AUTOSAR XML (schema 3.1.2)
package /Components/SWC_VSLim
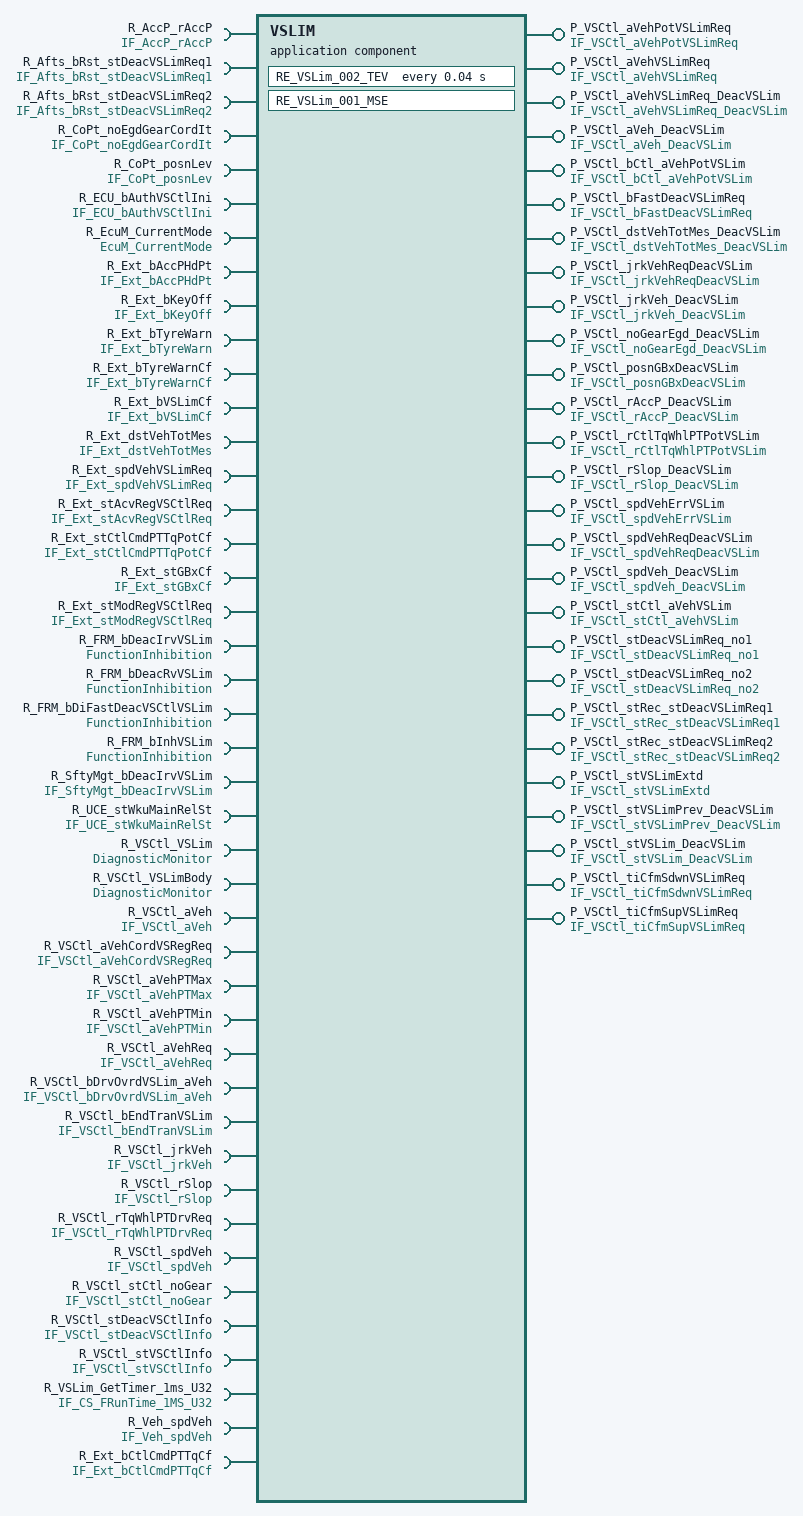
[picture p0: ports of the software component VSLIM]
  application software component type VSLIM  # VSLim
    27 x provide port:
      P_VSCtl_aVehPotVSLimReq: unqueued-sender-com-spec{data-element=VSCtl_aVehPotVSLimReq, can-invalidate=false, init-value=ConstantValue}, provided-interface=IF_VSCtl_aVehPotVSLimReq
      P_VSCtl_aVehVSLimReq: unqueued-sender-com-spec{data-element=VSCtl_aVehVSLimReq, can-invalidate=false, init-value=ConstantValue1}, provided-interface=IF_VSCtl_aVehVSLimReq
      P_VSCtl_aVehVSLimReq_DeacVSLim: unqueued-sender-com-spec{data-element=VSCtl_aVehVSLimReq_DeacVSLim, can-invalidate=false, init-value=C_SInt16_10240}, provided-interface=IF_VSCtl_aVehVSLimReq_DeacVSLim
      P_VSCtl_aVeh_DeacVSLim: unqueued-sender-com-spec{data-element=VSCtl_aVeh_DeacVSLim, can-invalidate=false, init-value=C_SInt16_0}, provided-interface=IF_VSCtl_aVeh_DeacVSLim
      P_VSCtl_bCtl_aVehPotVSLim: unqueued-sender-com-spec{data-element=VSCtl_bCtl_aVehPotVSLim, can-invalidate=false, init-value=ConstantValue3}, provided-interface=IF_VSCtl_bCtl_aVehPotVSLim
      P_VSCtl_bFastDeacVSLimReq: unqueued-sender-com-spec{data-element=VSCtl_bFastDeacVSLimReq, can-invalidate=false, init-value=C_Boolean_False}, provided-interface=IF_VSCtl_bFastDeacVSLimReq
      P_VSCtl_dstVehTotMes_DeacVSLim: unqueued-sender-com-spec{data-element=VSCtl_dstVehTotMes_DeacVSLim, can-invalidate=false, init-value=C_UInt32_0}, provided-interface=IF_VSCtl_dstVehTotMes_DeacVSLim
      P_VSCtl_jrkVehReqDeacVSLim: unqueued-sender-com-spec{data-element=VSCtl_jrkVehReqDeacVSLim, can-invalidate=false, init-value=C_SInt16_05}, provided-interface=IF_VSCtl_jrkVehReqDeacVSLim
      P_VSCtl_jrkVeh_DeacVSLim: unqueued-sender-com-spec{data-element=VSCtl_jrkVeh_DeacVSLim, can-invalidate=false, init-value=C_SInt16_07}, provided-interface=IF_VSCtl_jrkVeh_DeacVSLim
      P_VSCtl_noGearEgd_DeacVSLim: unqueued-sender-com-spec{data-element=VSCtl_noGearEgd_DeacVSLim, can-invalidate=false, init-value=C_SInt8_0}, provided-interface=IF_VSCtl_noGearEgd_DeacVSLim
      P_VSCtl_posnGBxDeacVSLim: unqueued-sender-com-spec{data-element=VSCtl_posnGBxDeacVSLim, can-invalidate=false, init-value=C_UInt8_0}, provided-interface=IF_VSCtl_posnGBxDeacVSLim
      P_VSCtl_rAccP_DeacVSLim: unqueued-sender-com-spec{data-element=VSCtl_rAccP_DeacVSLim, can-invalidate=false, init-value=C_UInt16_12800}, provided-interface=IF_VSCtl_rAccP_DeacVSLim
      P_VSCtl_rCtlTqWhlPTPotVSLim: unqueued-sender-com-spec{data-element=VSCtl_rCtlTqWhlPTPotVSLim, can-invalidate=false, init-value=ConstantValue9}, provided-interface=IF_VSCtl_rCtlTqWhlPTPotVSLim
      P_VSCtl_rSlop_DeacVSLim: unqueued-sender-com-spec{data-element=VSCtl_rSlop_DeacVSLim, can-invalidate=false, init-value=C_SInt16_011}, provided-interface=IF_VSCtl_rSlop_DeacVSLim
      P_VSCtl_spdVehErrVSLim: unqueued-sender-com-spec{data-element=VSCtl_spdVehErrVSLim, can-invalidate=false, init-value=C_SInt16_013}, provided-interface=IF_VSCtl_spdVehErrVSLim
      P_VSCtl_spdVehReqDeacVSLim: unqueued-sender-com-spec{data-element=VSCtl_spdVehReqDeacVSLim, can-invalidate=false, init-value=C_UInt8_015}, provided-interface=IF_VSCtl_spdVehReqDeacVSLim
      P_VSCtl_spdVeh_DeacVSLim: unqueued-sender-com-spec{data-element=VSCtl_spdVeh_DeacVSLim, can-invalidate=false, init-value=C_UInt16_0}, provided-interface=IF_VSCtl_spdVeh_DeacVSLim
      P_VSCtl_stCtl_aVehVSLim: unqueued-sender-com-spec{data-element=VSCtl_stCtl_aVehVSLim, can-invalidate=false, init-value=ConstantValue17}, provided-interface=IF_VSCtl_stCtl_aVehVSLim
      P_VSCtl_stDeacVSLimReq_no1: unqueued-sender-com-spec{data-element=VSCtl_stDeacVSLimReq_no1, can-invalidate=false, init-value=C_UInt32_16777215}, provided-interface=IF_VSCtl_stDeacVSLimReq_no1
      P_VSCtl_stDeacVSLimReq_no2: unqueued-sender-com-spec{data-element=VSCtl_stDeacVSLimReq_no2, can-invalidate=false, init-value=C_UInt32_1677721519}, provided-interface=IF_VSCtl_stDeacVSLimReq_no2
      P_VSCtl_stRec_stDeacVSLimReq1: unqueued-sender-com-spec{data-element=VSCtl_stRec_stDeacVSLimReq1, can-invalidate=false, init-value=C_UInt8_021}, provided-interface=IF_VSCtl_stRec_stDeacVSLimReq1
      P_VSCtl_stRec_stDeacVSLimReq2: unqueued-sender-com-spec{data-element=VSCtl_stRec_stDeacVSLimReq2, can-invalidate=false, init-value=C_UInt8_023}, provided-interface=IF_VSCtl_stRec_stDeacVSLimReq2
      P_VSCtl_stVSLimExtd: unqueued-sender-com-spec{data-element=VSCtl_stVSLimExtd, can-invalidate=false, init-value=C_UInt8_025}, provided-interface=IF_VSCtl_stVSLimExtd
      P_VSCtl_stVSLimPrev_DeacVSLim: unqueued-sender-com-spec{data-element=VSCtl_stVSLimPrev_DeacVSLim, can-invalidate=false, init-value=C_UInt8_027}, provided-interface=IF_VSCtl_stVSLimPrev_DeacVSLim
      P_VSCtl_stVSLim_DeacVSLim: unqueued-sender-com-spec{data-element=VSCtl_stVSLim_DeacVSLim, can-invalidate=false, init-value=C_UInt8_029}, provided-interface=IF_VSCtl_stVSLim_DeacVSLim
      P_VSCtl_tiCfmSdwnVSLimReq: unqueued-sender-com-spec{data-element=VSCtl_tiCfmSdwnVSLimReq, can-invalidate=false, init-value=ConstantValue31}, provided-interface=IF_VSCtl_tiCfmSdwnVSLimReq
      P_VSCtl_tiCfmSupVSLimReq: unqueued-sender-com-spec{data-element=VSCtl_tiCfmSupVSLimReq, can-invalidate=false, init-value=ConstantValue33}, provided-interface=IF_VSCtl_tiCfmSupVSLimReq
    43 x require port:
      R_AccP_rAccP: unqueued-receiver-com-spec{data-element=AccP_rAccP, init-value=ConstantValue35, resync-time=0}, required-interface=IF_AccP_rAccP
      R_Afts_bRst_stDeacVSLimReq1: unqueued-receiver-com-spec{data-element=Afts_bRst_stDeacVSLimReq1, init-value=C_Boolean_False37, resync-time=0}, required-interface=IF_Afts_bRst_stDeacVSLimReq1
      R_Afts_bRst_stDeacVSLimReq2: unqueued-receiver-com-spec{data-element=Afts_bRst_stDeacVSLimReq2, init-value=C_Boolean_False39, resync-time=0}, required-interface=IF_Afts_bRst_stDeacVSLimReq2
      R_CoPt_noEgdGearCordIt: unqueued-receiver-com-spec{data-element=CoPt_noEgdGearCordIt, init-value=ConstantValue41, resync-time=0}, required-interface=IF_CoPt_noEgdGearCordIt
      R_CoPt_posnLev: unqueued-receiver-com-spec{data-element=CoPt_posnLev, init-value=ConstantValue43, resync-time=0}, required-interface=IF_CoPt_posnLev
      R_ECU_bAuthVSCtlIni: unqueued-receiver-com-spec{data-element=ECU_bAuthVSCtlIni, init-value=ConstantValue45, resync-time=0}, required-interface=IF_ECU_bAuthVSCtlIni
      R_EcuM_CurrentMode: required-interface=EcuM_CurrentMode  # Requirement: 01552_09_00532-SSTG-C007(2)
      R_Ext_bAccPHdPt: unqueued-receiver-com-spec{data-element=Ext_bAccPHdPt, init-value=C_Boolean_False47, resync-time=0}, required-interface=IF_Ext_bAccPHdPt
      R_Ext_bKeyOff: unqueued-receiver-com-spec{data-element=Ext_bKeyOff, init-value=ConstantValue49, resync-time=0}, required-interface=IF_Ext_bKeyOff
      R_Ext_bTyreWarn: unqueued-receiver-com-spec{data-element=Ext_bTyreWarn, init-value=C_Boolean_False51, resync-time=0}, required-interface=IF_Ext_bTyreWarn
      R_Ext_bTyreWarnCf: unqueued-receiver-com-spec{data-element=Ext_bTyreWarnCf, init-value=C_Boolean_False53, resync-time=0}, required-interface=IF_Ext_bTyreWarnCf
      R_Ext_bVSLimCf: unqueued-receiver-com-spec{data-element=Ext_bVSLimCf, init-value=ConstantValue55, resync-time=0}, required-interface=IF_Ext_bVSLimCf
      R_Ext_dstVehTotMes: unqueued-receiver-com-spec{data-element=Ext_dstVehTotMes, init-value=ConstantValue57, resync-time=0}, required-interface=IF_Ext_dstVehTotMes
      R_Ext_spdVehVSLimReq: unqueued-receiver-com-spec{data-element=Ext_spdVehVSLimReq, init-value=C_UInt8_059, resync-time=0}, required-interface=IF_Ext_spdVehVSLimReq
      R_Ext_stAcvRegVSCtlReq: unqueued-receiver-com-spec{data-element=Ext_stAcvRegVSCtlReq, init-value=C_UInt8_061, resync-time=0}, required-interface=IF_Ext_stAcvRegVSCtlReq
      R_Ext_stCtlCmdPTTqPotCf: unqueued-receiver-com-spec{data-element=Ext_stCtlCmdPTTqPotCf, init-value=ConstantValue63, resync-time=0}, required-interface=IF_Ext_stCtlCmdPTTqPotCf
      R_Ext_stGBxCf: unqueued-receiver-com-spec{data-element=Ext_stGBxCf, init-value=ConstantValue65, resync-time=0}, required-interface=IF_Ext_stGBxCf
      R_Ext_stModRegVSCtlReq: unqueued-receiver-com-spec{data-element=Ext_stModRegVSCtlReq, init-value=C_UInt8_067, resync-time=0}, required-interface=IF_Ext_stModRegVSCtlReq
      R_FRM_bDeacIrvVSLim: required-interface=FunctionInhibition
      R_FRM_bDeacRvVSLim: required-interface=FunctionInhibition
      R_FRM_bDiFastDeacVSCtlVSLim: required-interface=FunctionInhibition
      R_FRM_bInhVSLim: required-interface=FunctionInhibition
      R_SftyMgt_bDeacIrvVSLim: unqueued-receiver-com-spec{data-element=SftyMgt_bDeacIrvVSLim, init-value=C_Boolean_False69, resync-time=0}, required-interface=IF_SftyMgt_bDeacIrvVSLim
      R_UCE_stWkuMainRelSt: required-interface=IF_UCE_stWkuMainRelSt  # Requirement: 01552_09_00532-SSTG-C011(1)
      R_VSCtl_VSLim: required-interface=DiagnosticMonitor
      R_VSCtl_VSLimBody: required-interface=DiagnosticMonitor
      R_VSCtl_aVeh: unqueued-receiver-com-spec{data-element=VSCtl_aVeh, init-value=ConstantValue71, resync-time=0}, required-interface=IF_VSCtl_aVeh
      R_VSCtl_aVehCordVSRegReq: unqueued-receiver-com-spec{data-element=VSCtl_aVehCordVSRegReq, init-value=ConstantValue73, resync-time=0}, required-interface=IF_VSCtl_aVehCordVSRegReq
      R_VSCtl_aVehPTMax: unqueued-receiver-com-spec{data-element=VSCtl_aVehPTMax, init-value=ConstantValue75, resync-time=0}, required-interface=IF_VSCtl_aVehPTMax
      R_VSCtl_aVehPTMin: unqueued-receiver-com-spec{data-element=VSCtl_aVehPTMin, init-value=ConstantValue77, resync-time=0}, required-interface=IF_VSCtl_aVehPTMin
      R_VSCtl_aVehReq: unqueued-receiver-com-spec{data-element=VSCtl_aVehReq, init-value=ConstantValue79, resync-time=0}, required-interface=IF_VSCtl_aVehReq
      R_VSCtl_bDrvOvrdVSLim_aVeh: unqueued-receiver-com-spec{data-element=VSCtl_bDrvOvrdVSLim_aVeh, init-value=ConstantValue81, resync-time=0}, required-interface=IF_VSCtl_bDrvOvrdVSLim_aVeh
      R_VSCtl_bEndTranVSLim: unqueued-receiver-com-spec{data-element=VSCtl_bEndTranVSLim, init-value=ConstantValue83, resync-time=0}, required-interface=IF_VSCtl_bEndTranVSLim
      R_VSCtl_jrkVeh: unqueued-receiver-com-spec{data-element=VSCtl_jrkVeh, init-value=ConstantValue85, resync-time=0}, required-interface=IF_VSCtl_jrkVeh
      R_VSCtl_rSlop: unqueued-receiver-com-spec{data-element=VSCtl_rSlop, init-value=ConstantValue87, resync-time=0}, required-interface=IF_VSCtl_rSlop
      R_VSCtl_rTqWhlPTDrvReq: unqueued-receiver-com-spec{data-element=VSCtl_rTqWhlPTDrvReq, init-value=ConstantValue89, resync-time=0}, required-interface=IF_VSCtl_rTqWhlPTDrvReq
      R_VSCtl_spdVeh: unqueued-receiver-com-spec{data-element=VSCtl_spdVeh, init-value=ConstantValue91, resync-time=0}, required-interface=IF_VSCtl_spdVeh
      R_VSCtl_stCtl_noGear: unqueued-receiver-com-spec{data-element=VSCtl_stCtl_noGear, init-value=C_UInt8_093, resync-time=0}, required-interface=IF_VSCtl_stCtl_noGear
      R_VSCtl_stDeacVSCtlInfo: unqueued-receiver-com-spec{data-element=VSCtl_stDeacVSCtlInfo, init-value=ConstantValue95, resync-time=0}, required-interface=IF_VSCtl_stDeacVSCtlInfo
      R_VSCtl_stVSCtlInfo: unqueued-receiver-com-spec{data-element=VSCtl_stVSCtlInfo, init-value=ConstantValue97, resync-time=0}, required-interface=IF_VSCtl_stVSCtlInfo
      R_VSLim_GetTimer_1ms_U32: required-interface=IF_CS_FRunTime_1MS_U32
      R_Veh_spdVeh: unqueued-receiver-com-spec{data-element=Veh_spdVeh, init-value=ConstantValue99, resync-time=0}, required-interface=IF_Veh_spdVeh
      R_Ext_bCtlCmdPTTqCf: unqueued-receiver-com-spec{data-element=Ext_bCtlCmdPTTqCf, init-value=ConstantValue101, resync-time=0}, required-interface=IF_Ext_bCtlCmdPTTqCf  # R_Ext_bVSMaxpCf
  61 x constant specification:
    C_Boolean_False
      value:
        boolean literal C_Boolean_False: type=DT_VSCtl_bFastDeacVSLimReq, value=false
    C_Boolean_False37
      value:
        boolean literal C_Boolean_False37: type=DT_Afts_bRst_stDeacVSLimReq1, value=false
    C_Boolean_False39
      value:
        boolean literal C_Boolean_False39: type=DT_Afts_bRst_stDeacVSLimReq2, value=false
    C_Boolean_False47
      value:
        boolean literal C_Boolean_False47: type=DT_Ext_bAccPHdPt, value=false
    C_Boolean_False51
      value:
        boolean literal C_Boolean_False51: type=DT_Ext_bTyreWarn, value=false
    C_Boolean_False53
      value:
        boolean literal C_Boolean_False53: type=DT_Ext_bTyreWarnCf, value=false
    C_Boolean_False69
      value:
        boolean literal C_Boolean_False69: type=DT_SftyMgt_bDeacIrvVSLim, value=false
    C_SInt16_0
      value:
        integer literal C_SInt16_0: type=DT_VSCtl_aVeh_DeacVSLim, value=0
    C_SInt16_011
      value:
        integer literal C_SInt16_011: type=DT_VSCtl_rSlop_DeacVSLim, value=0
    C_SInt16_013
      value:
        integer literal C_SInt16_013: type=DT_VSCtl_spdVehErrVSLim, value=0
    C_SInt16_05
      value:
        integer literal C_SInt16_05: type=DT_VSCtl_jrkVehReqDeacVSLim, value=0
    C_SInt16_07
      value:
        integer literal C_SInt16_07: type=DT_VSCtl_jrkVeh_DeacVSLim, value=0
    C_SInt16_10240
      value:
        integer literal C_SInt16_10240: type=DT_VSCtl_aVehVSLimReq_DeacVSLim, value=10240
    C_SInt8_0
      value:
        integer literal C_SInt8_0: type=DT_VSCtl_noGearEgd_DeacVSLim, value=0
    C_UInt16_0
      value:
        integer literal C_UInt16_0: type=DT_VSCtl_spdVeh_DeacVSLim, value=0
    C_UInt16_12800
      value:
        integer literal C_UInt16_12800: type=DT_VSCtl_rAccP_DeacVSLim, value=12800
    C_UInt32_0
      value:
        integer literal C_UInt32_0: type=DT_VSCtl_dstVehTotMes_DeacVSLim, value=0
    C_UInt32_16777215
      value:
        integer literal C_UInt32_16777215: type=DT_VSCtl_stDeacVSLimReq_no1, value=16777215
    C_UInt32_1677721519
      value:
        integer literal C_UInt32_1677721519: type=DT_VSCtl_stDeacVSLimReq_no2, value=16777215
    C_UInt8_0
      value:
        integer literal C_UInt8_0: type=DT_VSCtl_posnGBxDeacVSLim, value=0
    C_UInt8_015
      value:
        integer literal C_UInt8_015: type=DT_VSCtl_spdVehReqDeacVSLim, value=0
    C_UInt8_021
      value:
        integer literal C_UInt8_021: type=DT_VSCtl_stRec_stDeacVSLimReq1, value=0
    C_UInt8_023
      value:
        integer literal C_UInt8_023: type=DT_VSCtl_stRec_stDeacVSLimReq2, value=0
    C_UInt8_025
      value:
        integer literal C_UInt8_025: type=DT_VSCtl_stVSLimExtd, value=0
    C_UInt8_027
      value:
        integer literal C_UInt8_027: type=DT_VSCtl_stVSLimPrev_DeacVSLim, value=0
    C_UInt8_029
      value:
        integer literal C_UInt8_029: type=DT_VSCtl_stVSLim_DeacVSLim, value=0
    C_UInt8_059
      value:
        integer literal C_UInt8_059: type=DT_Ext_spdVehVSLimReq, value=255
    C_UInt8_061
      value:
        integer literal C_UInt8_061: type=DT_Ext_stAcvRegVSCtlReq, value=0
    C_UInt8_067
      value:
        integer literal C_UInt8_067: type=DT_Ext_stModRegVSCtlReq, value=0
    C_UInt8_093
      value:
        integer literal C_UInt8_093: type=DT_VSCtl_stCtl_noGear, value=0
    ConstantValue
      value:
        integer literal ConstantValue: type=DT_VSCtl_aVehPotVSLimReq, value=0
    ConstantValue1
      value:
        integer literal ConstantValue1: type=DT_VSCtl_aVehVSLimReq, value=0
    ConstantValue101
      value:
        boolean literal ConstantValue101: type=DT_Ext_bCtlCmdPTTqCf, value=false
    ConstantValue17
      value:
        integer literal ConstantValue17: type=DT_VSCtl_stCtl_aVehVSLim, value=0
    ConstantValue3
      value:
        integer literal ConstantValue3: type=DT_VSCtl_bCtl_aVehPotVSLim, value=0
    ConstantValue31
      value:
        integer literal ConstantValue31: type=DT_VSCtl_tiCfmSdwnVSLimReq, value=0
    ConstantValue33
      value:
        integer literal ConstantValue33: type=DT_VSCtl_tiCfmSupVSLimReq, value=0
    ConstantValue35
      value:
        integer literal ConstantValue35: type=DT_AccP_rAccP, value=0
    ConstantValue41
      value:
        integer literal ConstantValue41: type=DT_CoPt_noEgdGearCordIt, value=0
    ConstantValue43
      value:
        integer literal ConstantValue43: type=DT_CoPt_posnLev, value=0
    ConstantValue45
      value:
        boolean literal ConstantValue45: type=DT_ECU_bAuthVSCtlIni, value=false
    ConstantValue49
      value:
        boolean literal ConstantValue49: type=DT_Ext_bKeyOff, value=false
    ConstantValue55
      value:
        boolean literal ConstantValue55: type=DT_Ext_bVSLimCf, value=false
    ConstantValue57
      value:
        integer literal ConstantValue57: type=DT_Ext_dstVehTotMes, value=0
    ConstantValue63
      value:
        integer literal ConstantValue63: type=DT_Ext_stCtlCmdPTTqPotCf, value=0
    ConstantValue65
      value:
        integer literal ConstantValue65: type=DT_Ext_stGBxCf, value=0
    ConstantValue71
      value:
        integer literal ConstantValue71: type=DT_VSCtl_aVeh, value=0
    ConstantValue73
      value:
        integer literal ConstantValue73: type=DT_VSCtl_aVehCordVSRegReq, value=-10240
    ConstantValue75
      value:
        integer literal ConstantValue75: type=DT_VSCtl_aVehPTMax, value=0
    ConstantValue77
      value:
        integer literal ConstantValue77: type=DT_VSCtl_aVehPTMin, value=0
    ConstantValue79
      value:
        integer literal ConstantValue79: type=DT_VSCtl_aVehReq, value=-10240
    ConstantValue81
      value:
        boolean literal ConstantValue81: type=DT_VSCtl_bDrvOvrdVSLim_aVeh, value=true
    ConstantValue83
      value:
        boolean literal ConstantValue83: type=DT_VSCtl_bEndTranVSLim, value=true
    ConstantValue85
      value:
        integer literal ConstantValue85: type=DT_VSCtl_jrkVeh, value=0
    ConstantValue87
      value:
        integer literal ConstantValue87: type=DT_VSCtl_rSlop, value=0
    ConstantValue89
      value:
        integer literal ConstantValue89: type=DT_VSCtl_rTqWhlPTDrvReq, value=0
    ConstantValue9
      value:
        integer literal ConstantValue9: type=DT_VSCtl_rCtlTqWhlPTPotVSLim, value=0
    ConstantValue91
      value:
        integer literal ConstantValue91: type=DT_VSCtl_spdVeh, value=0
    ConstantValue95
      value:
        integer literal ConstantValue95: type=DT_VSCtl_stDeacVSCtlInfo, value=32
    ConstantValue97
      value:
        integer literal ConstantValue97: type=DT_VSCtl_stVSCtlInfo, value=0
    ConstantValue99
      value:
        integer literal ConstantValue99: type=DT_Veh_spdVeh, value=0
  internal behavior IB_VSLim: component=VSLIM
    timing event EV_VSLim_002_TEV: mode-dependency=dependent-on-mode=[R_UCE_stWkuMainRelSt.RCD_stWkuMainRelSt.Invalid, R_UCE_stWkuMainRelSt.RCD_stWkuMainRelSt.PostMainWakeUp, R_UCE_stWkuMainRelSt.RCD_stWkuMainRelSt.PreMainWakeUp], start-on-event=RE_VSLim_002_TEV, period=0.04
    mode switch event EV_VSLim_001_MSE: start-on-event=RE_VSLim_001_MSE, activation=ENTRY, mode=R_EcuM_CurrentMode.currentMode.RUN
    runnable RE_VSLim_001_MSE  # RE_01552_10_02848_10ms_init
      27 x data send point:
        ds_VSCtl_stVSLimExtd: data-element=P_VSCtl_stVSLimExtd.VSCtl_stVSLimExtd
        ds_VSCtl_posnGBxDeacVSLim: data-element=P_VSCtl_posnGBxDeacVSLim.VSCtl_posnGBxDeacVSLim
        ds_VSCtl_tiCfmSupVSLimReq: data-element=P_VSCtl_tiCfmSupVSLimReq.VSCtl_tiCfmSupVSLimReq
        ds_VSCtl_rAccP_DeacVSLim: data-element=P_VSCtl_rAccP_DeacVSLim.VSCtl_rAccP_DeacVSLim
        ds_VSCtl_jrkVeh_DeacVSLim: data-element=P_VSCtl_jrkVeh_DeacVSLim.VSCtl_jrkVeh_DeacVSLim
        ds_VSCtl_stRec_stDeacVSLimReq1: data-element=P_VSCtl_stRec_stDeacVSLimReq1.VSCtl_stRec_stDeacVSLimReq1
        ds_VSCtl_bFastDeacVSLimReq: data-element=P_VSCtl_bFastDeacVSLimReq.VSCtl_bFastDeacVSLimReq
        ds_VSCtl_aVeh_DeacVSLim: data-element=P_VSCtl_aVeh_DeacVSLim.VSCtl_aVeh_DeacVSLim
        ds_VSCtl_stCtl_aVehVSLim: data-element=P_VSCtl_stCtl_aVehVSLim.VSCtl_stCtl_aVehVSLim
        ds_VSCtl_aVehPotVSLimReq: data-element=P_VSCtl_aVehPotVSLimReq.VSCtl_aVehPotVSLimReq
        ds_VSCtl_spdVeh_DeacVSLim: data-element=P_VSCtl_spdVeh_DeacVSLim.VSCtl_spdVeh_DeacVSLim
        ds_VSCtl_stDeacVSLimReq_no1: data-element=P_VSCtl_stDeacVSLimReq_no1.VSCtl_stDeacVSLimReq_no1
        ds_VSCtl_dstVehTotMes_DeacVSLim: data-element=P_VSCtl_dstVehTotMes_DeacVSLim.VSCtl_dstVehTotMes_DeacVSLim
        ds_VSCtl_rSlop_DeacVSLim: data-element=P_VSCtl_rSlop_DeacVSLim.VSCtl_rSlop_DeacVSLim
        ds_VSCtl_stVSLim_DeacVSLim: data-element=P_VSCtl_stVSLim_DeacVSLim.VSCtl_stVSLim_DeacVSLim
        ds_VSCtl_aVehVSLimReq: data-element=P_VSCtl_aVehVSLimReq.VSCtl_aVehVSLimReq
        ds_VSCtl_spdVehReqDeacVSLim: data-element=P_VSCtl_spdVehReqDeacVSLim.VSCtl_spdVehReqDeacVSLim
        ds_VSCtl_aVehVSLimReq_DeacVSLim: data-element=P_VSCtl_aVehVSLimReq_DeacVSLim.VSCtl_aVehVSLimReq_DeacVSLim
        ds_VSCtl_rCtlTqWhlPTPotVSLim: data-element=P_VSCtl_rCtlTqWhlPTPotVSLim.VSCtl_rCtlTqWhlPTPotVSLim
        ds_VSCtl_stDeacVSLimReq_no2: data-element=P_VSCtl_stDeacVSLimReq_no2.VSCtl_stDeacVSLimReq_no2
        ds_VSCtl_spdVehErrVSLim: data-element=P_VSCtl_spdVehErrVSLim.VSCtl_spdVehErrVSLim
        ds_VSCtl_noGearEgd_DeacVSLim: data-element=P_VSCtl_noGearEgd_DeacVSLim.VSCtl_noGearEgd_DeacVSLim
        ds_VSCtl_tiCfmSdwnVSLimReq: data-element=P_VSCtl_tiCfmSdwnVSLimReq.VSCtl_tiCfmSdwnVSLimReq
        ds_VSCtl_stRec_stDeacVSLimReq2: data-element=P_VSCtl_stRec_stDeacVSLimReq2.VSCtl_stRec_stDeacVSLimReq2
        ds_VSCtl_jrkVehReqDeacVSLim: data-element=P_VSCtl_jrkVehReqDeacVSLim.VSCtl_jrkVehReqDeacVSLim
        ds_VSCtl_stVSLimPrev_DeacVSLim: data-element=P_VSCtl_stVSLimPrev_DeacVSLim.VSCtl_stVSLimPrev_DeacVSLim
        ds_VSCtl_bCtl_aVehPotVSLim: data-element=P_VSCtl_bCtl_aVehPotVSLim.VSCtl_bCtl_aVehPotVSLim
      sync call ssp_GetTimer_1ms_U32: operation=R_VSLim_GetTimer_1ms_U32.GetTimer_1ms_U32
    runnable RE_VSLim_002_TEV  # RE_01552_10_02848_40ms
      34 x data receive point:
        dr_AccP_rAccP: data-element=R_AccP_rAccP.AccP_rAccP
        dr_Ext_bVSLimCf: data-element=R_Ext_bVSLimCf.Ext_bVSLimCf
        dr_VSCtl_bDrvOvrdVSLim_aVeh: data-element=R_VSCtl_bDrvOvrdVSLim_aVeh.VSCtl_bDrvOvrdVSLim_aVeh
        dr_Ext_stModRegVSCtlReq: data-element=R_Ext_stModRegVSCtlReq.Ext_stModRegVSCtlReq
        dr_SftyMgt_bDeacIrvVSLim: data-element=R_SftyMgt_bDeacIrvVSLim.SftyMgt_bDeacIrvVSLim
        dr_VSCtl_jrkVeh: data-element=R_VSCtl_jrkVeh.VSCtl_jrkVeh
        dr_VSCtl_aVehReq: data-element=R_VSCtl_aVehReq.VSCtl_aVehReq
        dr_Afts_bRst_stDeacVSLimReq1: data-element=R_Afts_bRst_stDeacVSLimReq1.Afts_bRst_stDeacVSLimReq1
        dr_VSCtl_aVeh: data-element=R_VSCtl_aVeh.VSCtl_aVeh
        dr_CoPt_posnLev: data-element=R_CoPt_posnLev.CoPt_posnLev
        dr_VSCtl_stDeacVSCtlInfo: data-element=R_VSCtl_stDeacVSCtlInfo.VSCtl_stDeacVSCtlInfo
        dr_Veh_spdVeh: data-element=R_Veh_spdVeh.Veh_spdVeh
        dr_CoPt_noEgdGearCordIt: data-element=R_CoPt_noEgdGearCordIt.CoPt_noEgdGearCordIt
        dr_VSCtl_spdVeh: data-element=R_VSCtl_spdVeh.VSCtl_spdVeh
        dr_VSCtl_rTqWhlPTDrvReq: data-element=R_VSCtl_rTqWhlPTDrvReq.VSCtl_rTqWhlPTDrvReq
        dr_Ext_spdVehVSLimReq: data-element=R_Ext_spdVehVSLimReq.Ext_spdVehVSLimReq
        dr_Afts_bRst_stDeacVSLimReq2: data-element=R_Afts_bRst_stDeacVSLimReq2.Afts_bRst_stDeacVSLimReq2
        dr_Ext_dstVehTotMes: data-element=R_Ext_dstVehTotMes.Ext_dstVehTotMes
        dr_Ext_stGBxCf: data-element=R_Ext_stGBxCf.Ext_stGBxCf
        dr_VSCtl_stVSCtlInfo: data-element=R_VSCtl_stVSCtlInfo.VSCtl_stVSCtlInfo
        dr_Ext_stCtlCmdPTTqPotCf: data-element=R_Ext_stCtlCmdPTTqPotCf.Ext_stCtlCmdPTTqPotCf
        dr_VSCtl_aVehCordVSRegReq: data-element=R_VSCtl_aVehCordVSRegReq.VSCtl_aVehCordVSRegReq
        dr_Ext_bKeyOff: data-element=R_Ext_bKeyOff.Ext_bKeyOff
        dr_VSCtl_bEndTranVSLim: data-element=R_VSCtl_bEndTranVSLim.VSCtl_bEndTranVSLim
        dr_Ext_bTyreWarnCf: data-element=R_Ext_bTyreWarnCf.Ext_bTyreWarnCf
        dr_Ext_stAcvRegVSCtlReq: data-element=R_Ext_stAcvRegVSCtlReq.Ext_stAcvRegVSCtlReq
        dr_VSCtl_aVehPTMax: data-element=R_VSCtl_aVehPTMax.VSCtl_aVehPTMax
        dr_VSCtl_aVehPTMin: data-element=R_VSCtl_aVehPTMin.VSCtl_aVehPTMin
        dr_Ext_bTyreWarn: data-element=R_Ext_bTyreWarn.Ext_bTyreWarn
        dr_VSCtl_rSlop: data-element=R_VSCtl_rSlop.VSCtl_rSlop
        dr_ECU_bAuthVSCtlIni: data-element=R_ECU_bAuthVSCtlIni.ECU_bAuthVSCtlIni
        dr_Ext_bAccPHdPt: data-element=R_Ext_bAccPHdPt.Ext_bAccPHdPt
        DRP_R_Ext_bCtlCmdPTTqCf_Ext_bCtlCmdPTTqCf: data-element=R_Ext_bCtlCmdPTTqCf.Ext_bCtlCmdPTTqCf
        dr_VSCtl_stCtl_noGear: data-element=R_VSCtl_stCtl_noGear.VSCtl_stCtl_noGear
      27 x data send point:
        ds_VSCtl_tiCfmSupVSLimReq: data-element=P_VSCtl_tiCfmSupVSLimReq.VSCtl_tiCfmSupVSLimReq
        ds_VSCtl_rSlop_DeacVSLim: data-element=P_VSCtl_rSlop_DeacVSLim.VSCtl_rSlop_DeacVSLim
        ds_VSCtl_dstVehTotMes_DeacVSLim: data-element=P_VSCtl_dstVehTotMes_DeacVSLim.VSCtl_dstVehTotMes_DeacVSLim
        ds_VSCtl_stVSLimPrev_DeacVSLim: data-element=P_VSCtl_stVSLimPrev_DeacVSLim.VSCtl_stVSLimPrev_DeacVSLim
        ds_VSCtl_spdVehErrVSLim: data-element=P_VSCtl_spdVehErrVSLim.VSCtl_spdVehErrVSLim
        ds_VSCtl_jrkVeh_DeacVSLim: data-element=P_VSCtl_jrkVeh_DeacVSLim.VSCtl_jrkVeh_DeacVSLim
        ds_VSCtl_stVSLimExtd: data-element=P_VSCtl_stVSLimExtd.VSCtl_stVSLimExtd
        ds_VSCtl_stVSLim_DeacVSLim: data-element=P_VSCtl_stVSLim_DeacVSLim.VSCtl_stVSLim_DeacVSLim
        ds_VSCtl_spdVeh_DeacVSLim: data-element=P_VSCtl_spdVeh_DeacVSLim.VSCtl_spdVeh_DeacVSLim
        ds_VSCtl_bCtl_aVehPotVSLim: data-element=P_VSCtl_bCtl_aVehPotVSLim.VSCtl_bCtl_aVehPotVSLim
        ds_VSCtl_bFastDeacVSLimReq: data-element=P_VSCtl_bFastDeacVSLimReq.VSCtl_bFastDeacVSLimReq
        ds_VSCtl_stRec_stDeacVSLimReq2: data-element=P_VSCtl_stRec_stDeacVSLimReq2.VSCtl_stRec_stDeacVSLimReq2
        ds_VSCtl_aVehVSLimReq: data-element=P_VSCtl_aVehVSLimReq.VSCtl_aVehVSLimReq
        ds_VSCtl_jrkVehReqDeacVSLim: data-element=P_VSCtl_jrkVehReqDeacVSLim.VSCtl_jrkVehReqDeacVSLim
        ds_VSCtl_aVehPotVSLimReq: data-element=P_VSCtl_aVehPotVSLimReq.VSCtl_aVehPotVSLimReq
        ds_VSCtl_rCtlTqWhlPTPotVSLim: data-element=P_VSCtl_rCtlTqWhlPTPotVSLim.VSCtl_rCtlTqWhlPTPotVSLim
        ds_VSCtl_spdVehReqDeacVSLim: data-element=P_VSCtl_spdVehReqDeacVSLim.VSCtl_spdVehReqDeacVSLim
        ds_VSCtl_stDeacVSLimReq_no1: data-element=P_VSCtl_stDeacVSLimReq_no1.VSCtl_stDeacVSLimReq_no1
        ds_VSCtl_rAccP_DeacVSLim: data-element=P_VSCtl_rAccP_DeacVSLim.VSCtl_rAccP_DeacVSLim
        ds_VSCtl_tiCfmSdwnVSLimReq: data-element=P_VSCtl_tiCfmSdwnVSLimReq.VSCtl_tiCfmSdwnVSLimReq
        ds_VSCtl_aVehVSLimReq_DeacVSLim: data-element=P_VSCtl_aVehVSLimReq_DeacVSLim.VSCtl_aVehVSLimReq_DeacVSLim
        ds_VSCtl_posnGBxDeacVSLim: data-element=P_VSCtl_posnGBxDeacVSLim.VSCtl_posnGBxDeacVSLim
        ds_VSCtl_stDeacVSLimReq_no2: data-element=P_VSCtl_stDeacVSLimReq_no2.VSCtl_stDeacVSLimReq_no2
        ds_VSCtl_stCtl_aVehVSLim: data-element=P_VSCtl_stCtl_aVehVSLim.VSCtl_stCtl_aVehVSLim
        ds_VSCtl_stRec_stDeacVSLimReq1: data-element=P_VSCtl_stRec_stDeacVSLimReq1.VSCtl_stRec_stDeacVSLimReq1
        ds_VSCtl_noGearEgd_DeacVSLim: data-element=P_VSCtl_noGearEgd_DeacVSLim.VSCtl_noGearEgd_DeacVSLim
        ds_VSCtl_aVeh_DeacVSLim: data-element=P_VSCtl_aVeh_DeacVSLim.VSCtl_aVeh_DeacVSLim
      7 x sync call:
        ssp_VSCtl_VSLim: operation=R_VSCtl_VSLim.SetEventStatus
        ssp_FRM_bDeacIrvVSLim: operation=R_FRM_bDeacIrvVSLim.GetFunctionPermission
        ssp_GetTimer_1ms_U32: operation=R_VSLim_GetTimer_1ms_U32.GetTimer_1ms_U32
        ssp_FRM_bDeacRvVSLim: operation=R_FRM_bDeacRvVSLim.GetFunctionPermission
        ssp_FRM_bDiFastDeacVSCtlVSLim: operation=R_FRM_bDiFastDeacVSCtlVSLim.GetFunctionPermission
        ssp_VSCtl_VSLimBody: operation=R_VSCtl_VSLimBody.SetEventStatus
        ssp_FRM_bInhVSLim: operation=R_FRM_bInhVSLim.GetFunctionPermission
  swc implementation Imp_VSLim: programming-language=C, behavior=IB_VSLim
    code-descriptors:
      code CodeDescriptor: type=SRC
        7 x xfile:
          VSLIM_Det_State_Diag_Mnt_c: url=VSLIM_Det_State_Diag_Mnt.c
          VSLIM_Fct_Mode_c: url=VSLIM_Fct_Mode.c
          VSLim_h: url=VSLim.h
          VSLIM_Det_Cond_Func_c: url=VSLIM_Det_Cond_Func.c
          VSLim_MemMap_h: url=VSLim_MemMap.h
          VSLim_c: url=VSLim.c
          VSLIM_Veh_Spd_Ctrl_c: url=VSLIM_Veh_Spd_Ctrl.c
